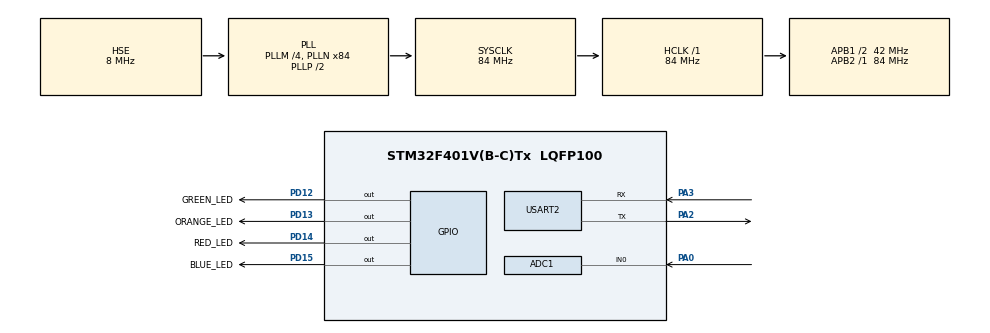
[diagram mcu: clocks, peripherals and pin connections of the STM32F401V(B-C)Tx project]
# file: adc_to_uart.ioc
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ADC1.Channel-4\#ChannelRegularConversion=ADC_CHANNEL_0
ADC1.Channel-5\#ChannelRegularConversion=ADC_CHANNEL_TEMPSENSOR
ADC1.Channel-6\#ChannelRegularConversion=ADC_CHANNEL_VREFINT
ADC1.ClockPrescaler=ADC_CLOCKPRESCALER_PCLK_DIV4
ADC1.ContinuousConvMode=ENABLE
ADC1.DMAContinuousRequests=ENABLE
ADC1.DataAlign=ADC_DATAALIGN_RIGHT
ADC1.DiscontinuousConvMode=DISABLE
ADC1.EOCSelection=EOC_SINGLE_CONV
ADC1.EnableAnalogWatchDog=false
ADC1.ExternalTrigConvEdge=ADC_EXTERNALTRIGCONVEDGE_NONE
ADC1.InjNumberOfConversion=0
ADC1.NbrOfConversion=3
ADC1.NbrOfConversionFlag=1
ADC1.Rank-4\#ChannelRegularConversion=1
ADC1.Rank-5\#ChannelRegularConversion=2
ADC1.Rank-6\#ChannelRegularConversion=3
ADC1.Resolution=ADC_RESOLUTION12b
ADC1.SamplingTime-4\#ChannelRegularConversion=ADC_SAMPLETIME_480CYCLES
ADC1.SamplingTime-5\#ChannelRegularConversion=ADC_SAMPLETIME_480CYCLES
ADC1.SamplingTime-6\#ChannelRegularConversion=ADC_SAMPLETIME_480CYCLES
ADC1.ScanConvMode=ENABLE
ADC1.master=1
Dma.ADC1.1.Channel=DMA_CHANNEL_0
Dma.ADC1.1.Direction=DMA_PERIPH_TO_MEMORY
Dma.ADC1.1.FIFOMode=DMA_FIFOMODE_DISABLE
Dma.ADC1.1.Instance=DMA2_Stream0
Dma.ADC1.1.MemDataAlignment=DMA_MDATAALIGN_WORD
Dma.ADC1.1.MemInc=DMA_MINC_ENABLE
Dma.ADC1.1.Mode=DMA_CIRCULAR
Dma.ADC1.1.PeriphDataAlignment=DMA_PDATAALIGN_WORD
Dma.ADC1.1.PeriphInc=DMA_PINC_DISABLE
Dma.ADC1.1.Priority=DMA_PRIORITY_LOW
Dma.Request0=USART2_TX
Dma.Request1=ADC1
Dma.USART2_TX.0.Channel=DMA_CHANNEL_4
Dma.USART2_TX.0.Direction=DMA_MEMORY_TO_PERIPH
Dma.USART2_TX.0.FIFOMode=DMA_FIFOMODE_DISABLE
Dma.USART2_TX.0.Instance=DMA1_Stream6
Dma.USART2_TX.0.MemDataAlignment=DMA_MDATAALIGN_BYTE
Dma.USART2_TX.0.MemInc=DMA_MINC_ENABLE
Dma.USART2_TX.0.Mode=DMA_NORMAL
Dma.USART2_TX.0.PeriphDataAlignment=DMA_PDATAALIGN_BYTE
Dma.USART2_TX.0.PeriphInc=DMA_PINC_DISABLE
Dma.USART2_TX.0.Priority=DMA_PRIORITY_LOW
Mcu.Family=STM32F4
Mcu.Name=STM32F401V(B-C)Tx
Mcu.Package=LQFP100
NVIC.ADC_IRQn=true\:0\:0\:false
NVIC.DMA1_Stream6_IRQn=true\:0\:0\:false
NVIC.DMA2_Stream0_IRQn=true\:0\:0\:false
NVIC.PriorityGroup=NVIC_PRIORITYGROUP_4
NVIC.TIM1_UP_TIM10_IRQn=true\:0\:0\:false
NVIC.TIM2_IRQn=true\:0\:0\:false
NVIC.USART2_IRQn=true\:0\:0\:false
PA0-WKUP.Signal=ADCx_IN0
PA2.Mode=Asynchronous
PA2.Signal=USART2_TX
PA3.Mode=Asynchronous
PA3.Signal=USART2_RX
PD12.GPIO_Label=GREEN_LED
PD12.Signal=GPIO_Output
PD13.GPIO_Label=ORANGE_LED
PD13.Signal=GPIO_Output
PD14.GPIO_Label=RED_LED
PD14.Signal=GPIO_Output
PD15.GPIO_Label=BLUE_LED
PD15.Signal=GPIO_Output
PH0\ -\ OSC_IN.Mode=HSE-External-Oscillator
PH0\ -\ OSC_IN.Signal=RCC_OSC_IN
PH1\ -\ OSC_OUT.Mode=HSE-External-Oscillator
PH1\ -\ OSC_OUT.Signal=RCC_OSC_OUT
ProjectManager.TargetToolchain=SW4STM32
RCC.48MHZClocksFreq_Value=42000000
RCC.AHBFreq_Value=84000000
RCC.APB1CLKDivider=RCC_HCLK_DIV2
RCC.APB1Freq_Value=42000000
RCC.APB1TimFreq_Value=84000000
RCC.APB2Freq_Value=84000000
RCC.APB2TimFreq_Value=84000000
RCC.CortexFreq_Value=84000000
RCC.HCLKFreq_Value=84000000
RCC.HSE_VALUE=8000000
RCC.HSI_VALUE=16000000
RCC.LSE_VALUE=32768
RCC.PLLM=4
RCC.PLLN=84
RCC.PLLSourceVirtual=RCC_PLLSOURCE_HSE
RCC.SYSCLKFreq_VALUE=84000000
RCC.SYSCLKSource=RCC_SYSCLKSOURCE_PLLCLK
RCC.VCOOutputFreq_Value=168000000
RCC.VDD_VALUE=3.3
SH.ADCx_IN0.0=ADC1_IN0,IN0
TIM1.Period=1000
TIM1.Prescaler=23999
TIM2.Period=1000
TIM2.Prescaler=31999
VP_ADC1_TempSens_Input.Mode=IN-TempSens
VP_ADC1_Vref_Input.Mode=IN-Vrefint
VP_TIM1_VS_ClockSourceINT.Mode=Internal
VP_TIM2_VS_ClockSourceINT.Mode=Internal
board=adc_to_uart

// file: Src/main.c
/**
  ******************************************************************************
  * File Name          : main.c
  * Description        : Main program body
  ******************************************************************************
  *
  * COPYRIGHT(c) 2016 STMicroelectronics
  *
  * Redistribution and use in source and binary forms, with or without modification,
  * are permitted provided that the following conditions are met:
  *   1. Redistributions of source code must retain the above copyright notice,
  *      this list of conditions and the following disclaimer.
  *   2. Redistributions in binary form must reproduce the above copyright notice,
  *      this list of conditions and the following disclaimer in the documentation
  *      and/or other materials provided with the distribution.
  *   3. Neither the name of STMicroelectronics nor the names of its contributors
  *      may be used to endorse or promote products derived from this software
  *      without specific prior written permission.
  *
  * THIS SOFTWARE IS PROVIDED BY THE COPYRIGHT HOLDERS AND CONTRIBUTORS "AS IS"
  * AND ANY EXPRESS OR IMPLIED WARRANTIES, INCLUDING, BUT NOT LIMITED TO, THE
  * IMPLIED WARRANTIES OF MERCHANTABILITY AND FITNESS FOR A PARTICULAR PURPOSE ARE
  * DISCLAIMED. IN NO EVENT SHALL THE COPYRIGHT HOLDER OR CONTRIBUTORS BE LIABLE
  * FOR ANY DIRECT, INDIRECT, INCIDENTAL, SPECIAL, EXEMPLARY, OR CONSEQUENTIAL
  * DAMAGES (INCLUDING, BUT NOT LIMITED TO, PROCUREMENT OF SUBSTITUTE GOODS OR
  * SERVICES; LOSS OF USE, DATA, OR PROFITS; OR BUSINESS INTERRUPTION) HOWEVER
  * CAUSED AND ON ANY THEORY OF LIABILITY, WHETHER IN CONTRACT, STRICT LIABILITY,
  * OR TORT (INCLUDING NEGLIGENCE OR OTHERWISE) ARISING IN ANY WAY OUT OF THE USE
  * OF THIS SOFTWARE, EVEN IF ADVISED OF THE POSSIBILITY OF SUCH DAMAGE.
  *
  ******************************************************************************
  */
#include "stm32f4xx_hal.h"

/* USER CODE BEGIN Includes */
#include "system.h"
#include "timer.h"
#include "adc.h"
#include "uart.h"
/* USER CODE END Includes */

ADC_HandleTypeDef hadc1;
DMA_HandleTypeDef hdma_adc1;

TIM_HandleTypeDef htim1;
TIM_HandleTypeDef htim2;

UART_HandleTypeDef huart2;
DMA_HandleTypeDef hdma_usart2_tx;

/* USER CODE BEGIN PV */
/* Private variables ---------------------------------------------------------*/

/* USER CODE END PV */

void SystemClock_Config(void);
static void MX_GPIO_Init(void);
static void MX_DMA_Init(void);
static void MX_ADC1_Init(void);
static void MX_TIM1_Init(void);
static void MX_TIM2_Init(void);
static void MX_USART2_UART_Init(void);

/* USER CODE BEGIN PFP */
/* Private function prototypes -----------------------------------------------*/

/* USER CODE END PFP */

int main(void)
{

  /* MCU Configuration----------------------------------------------------------*/

  /* Reset of all peripherals, Initializes the Flash interface and the Systick. */
  HAL_Init();

  /* Configure the system clock */
  SystemClock_Config();

  /* Initialize all configured peripherals */
  MX_GPIO_Init();
  MX_DMA_Init();
  MX_ADC1_Init();
  MX_TIM1_Init();
  MX_TIM2_Init();
  MX_USART2_UART_Init();

  /* USER CODE BEGIN 2 */

  //green led blink timer. Indicates how device is working
  startTimer1();

  //adc0 channel. Connect to my potentiometer
  adc_start();

  //pause to wait for ADC0 channel
  HAL_Delay(100);

  //start timer2 which get adc0 channel value and transmit it into UART
  startTimer2();

  /* USER CODE END 2 */

  /* Infinite loop */
  while (1)
  {

  }

}

/** System Clock Configuration
*/
void SystemClock_Config(void)
{

  RCC_OscInitTypeDef RCC_OscInitStruct;
  RCC_ClkInitTypeDef RCC_ClkInitStruct;

  __PWR_CLK_ENABLE();

  __HAL_PWR_VOLTAGESCALING_CONFIG(PWR_REGULATOR_VOLTAGE_SCALE2);

  RCC_OscInitStruct.OscillatorType = RCC_OSCILLATORTYPE_HSE;
  RCC_OscInitStruct.HSEState = RCC_HSE_ON;
  RCC_OscInitStruct.PLL.PLLState = RCC_PLL_ON;
  RCC_OscInitStruct.PLL.PLLSource = RCC_PLLSOURCE_HSE;
  RCC_OscInitStruct.PLL.PLLM = 4;
  RCC_OscInitStruct.PLL.PLLN = 84;
  RCC_OscInitStruct.PLL.PLLP = RCC_PLLP_DIV2;
  RCC_OscInitStruct.PLL.PLLQ = 4;
  HAL_RCC_OscConfig(&RCC_OscInitStruct);

  RCC_ClkInitStruct.ClockType = RCC_CLOCKTYPE_SYSCLK|RCC_CLOCKTYPE_PCLK1;
  RCC_ClkInitStruct.SYSCLKSource = RCC_SYSCLKSOURCE_PLLCLK;
  RCC_ClkInitStruct.AHBCLKDivider = RCC_SYSCLK_DIV1;
  RCC_ClkInitStruct.APB1CLKDivider = RCC_HCLK_DIV2;
  RCC_ClkInitStruct.APB2CLKDivider = RCC_HCLK_DIV1;
  HAL_RCC_ClockConfig(&RCC_ClkInitStruct, FLASH_LATENCY_2);

  HAL_SYSTICK_Config(HAL_RCC_GetHCLKFreq()/1000);

  HAL_SYSTICK_CLKSourceConfig(SYSTICK_CLKSOURCE_HCLK);

  /* SysTick_IRQn interrupt configuration */
  HAL_NVIC_SetPriority(SysTick_IRQn, 0, 0);
}

/* ADC1 init function */
void MX_ADC1_Init(void)
{

  ADC_ChannelConfTypeDef sConfig;

    /**Configure the global features of the ADC (Clock, Resolution, Data Alignment and number of conversion)
    */
  hadc1.Instance = ADC1;
  hadc1.Init.ClockPrescaler = ADC_CLOCKPRESCALER_PCLK_DIV4;
  hadc1.Init.Resolution = ADC_RESOLUTION12b;
  hadc1.Init.ScanConvMode = ENABLE;
  hadc1.Init.ContinuousConvMode = ENABLE;
  hadc1.Init.DiscontinuousConvMode = DISABLE;
  hadc1.Init.ExternalTrigConvEdge = ADC_EXTERNALTRIGCONVEDGE_NONE;
  hadc1.Init.DataAlign = ADC_DATAALIGN_RIGHT;
  hadc1.Init.NbrOfConversion = 3;
  hadc1.Init.DMAContinuousRequests = ENABLE;
  hadc1.Init.EOCSelection = EOC_SINGLE_CONV;
  HAL_ADC_Init(&hadc1);

    /**Configure for the selected ADC regular channel its corresponding rank in the sequencer and its sample time.
    */
  sConfig.Channel = ADC_CHANNEL_0;
  sConfig.Rank = 1;
  sConfig.SamplingTime = ADC_SAMPLETIME_480CYCLES;
  HAL_ADC_ConfigChannel(&hadc1, &sConfig);

    /**Configure for the selected ADC regular channel its corresponding rank in the sequencer and its sample time.
    */
  sConfig.Channel = ADC_CHANNEL_TEMPSENSOR;
  sConfig.Rank = 2;
  sConfig.SamplingTime = ADC_SAMPLETIME_3CYCLES;
  HAL_ADC_ConfigChannel(&hadc1, &sConfig);

    /**Configure for the selected ADC regular channel its corresponding rank in the sequencer and its sample time.
    */
  sConfig.Channel = ADC_CHANNEL_VREFINT;
  sConfig.Rank = 3;
  sConfig.SamplingTime = ADC_SAMPLETIME_480CYCLES;
  HAL_ADC_ConfigChannel(&hadc1, &sConfig);

}

/* TIM1 init function */
void MX_TIM1_Init(void)
{

  TIM_ClockConfigTypeDef sClockSourceConfig;
  TIM_MasterConfigTypeDef sMasterConfig;

  htim1.Instance = TIM1;
  htim1.Init.Prescaler = 23999;
  htim1.Init.CounterMode = TIM_COUNTERMODE_UP;
  htim1.Init.Period = 1000;
  htim1.Init.ClockDivision = TIM_CLOCKDIVISION_DIV1;
  htim1.Init.RepetitionCounter = 0;
  HAL_TIM_Base_Init(&htim1);

  sClockSourceConfig.ClockSource = TIM_CLOCKSOURCE_INTERNAL;
  HAL_TIM_ConfigClockSource(&htim1, &sClockSourceConfig);

  sMasterConfig.MasterOutputTrigger = TIM_TRGO_RESET;
  sMasterConfig.MasterSlaveMode = TIM_MASTERSLAVEMODE_DISABLE;
  HAL_TIMEx_MasterConfigSynchronization(&htim1, &sMasterConfig);

}

/* TIM2 init function */
void MX_TIM2_Init(void)
{

  TIM_ClockConfigTypeDef sClockSourceConfig;
  TIM_MasterConfigTypeDef sMasterConfig;

  htim2.Instance = TIM2;
  htim2.Init.Prescaler = 31999;
  htim2.Init.CounterMode = TIM_COUNTERMODE_UP;
  htim2.Init.Period = 1000;
  htim2.Init.ClockDivision = TIM_CLOCKDIVISION_DIV1;
  HAL_TIM_Base_Init(&htim2);

  sClockSourceConfig.ClockSource = TIM_CLOCKSOURCE_INTERNAL;
  HAL_TIM_ConfigClockSource(&htim2, &sClockSourceConfig);

  sMasterConfig.MasterOutputTrigger = TIM_TRGO_RESET;
  sMasterConfig.MasterSlaveMode = TIM_MASTERSLAVEMODE_DISABLE;
  HAL_TIMEx_MasterConfigSynchronization(&htim2, &sMasterConfig);

}

/* USART2 init function */
void MX_USART2_UART_Init(void)
{

  huart2.Instance = USART2;
  huart2.Init.BaudRate = 115200;
  huart2.Init.WordLength = UART_WORDLENGTH_8B;
  huart2.Init.StopBits = UART_STOPBITS_1;
  huart2.Init.Parity = UART_PARITY_NONE;
  huart2.Init.Mode = UART_MODE_TX_RX;
  huart2.Init.HwFlowCtl = UART_HWCONTROL_NONE;
  huart2.Init.OverSampling = UART_OVERSAMPLING_16;
  HAL_UART_Init(&huart2);

}

void MX_DMA_Init(void)
{
  /* DMA controller clock enable */
  __DMA1_CLK_ENABLE();
  __DMA2_CLK_ENABLE();

  /* DMA interrupt init */
  HAL_NVIC_SetPriority(DMA1_Stream6_IRQn, 0, 0);
  HAL_NVIC_EnableIRQ(DMA1_Stream6_IRQn);
  HAL_NVIC_SetPriority(DMA2_Stream0_IRQn, 0, 0);
  HAL_NVIC_EnableIRQ(DMA2_Stream0_IRQn);

}

/** Configure pins as
        * Analog
        * Input
        * Output
        * EVENT_OUT
        * EXTI
*/
void MX_GPIO_Init(void)
{

  GPIO_InitTypeDef GPIO_InitStruct;

  /* GPIO Ports Clock Enable */
  __GPIOH_CLK_ENABLE();
  __GPIOA_CLK_ENABLE();
  __GPIOD_CLK_ENABLE();

  /*Configure GPIO pins : GREEN_LED_Pin ORANGE_LED_Pin RED_LED_Pin BLUE_LED_Pin */
  GPIO_InitStruct.Pin = GREEN_LED_Pin|ORANGE_LED_Pin|RED_LED_Pin|BLUE_LED_Pin;
  GPIO_InitStruct.Mode = GPIO_MODE_OUTPUT_PP;
  GPIO_InitStruct.Pull = GPIO_NOPULL;
  GPIO_InitStruct.Speed = GPIO_SPEED_LOW;
  HAL_GPIO_Init(GPIOD, &GPIO_InitStruct);

}

/************************ (C) COPYRIGHT STMicroelectronics *****END OF FILE****/
